# ADuCM4050 register map
Vendor: Analog Devices; Series: ADuCM4050; File version: 1p0
CPU: CM4 r0p1, little endian, MPU, FPU, 3 interrupt priority bits
Registers are 32-bit, read-write, reset 0x0 unless marked. A register's access mark holds for its fields unless they carry their own. Offsets are from the block's base; [hi:lo] are bit positions; <NAME> marks a mode.

## PMG0 — Power Management
Base 0x4004C000
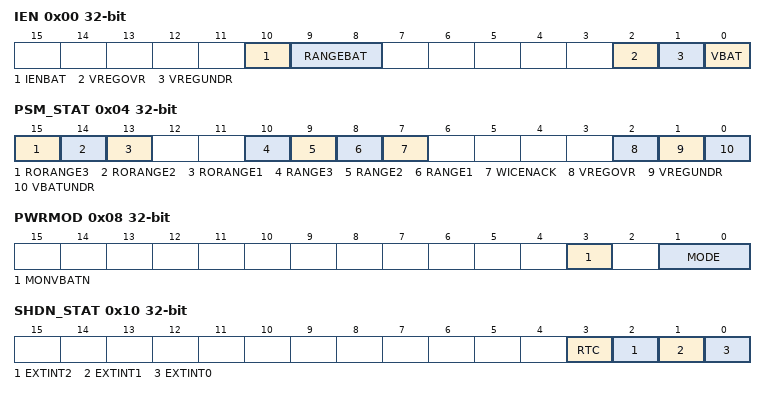
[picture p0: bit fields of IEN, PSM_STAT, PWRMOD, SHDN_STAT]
0x00 IEN — Power Supply Monitor Interrupt Enable
  [10] IENBAT range 0x00000000..0x00000001 — Interrupt Enable for VBAT Range
  [9:8] RANGEBAT — Battery Monitor Range
    0=region1 (Configure to generate interrupt if VBAT in Region1); 1=region2 (Configure to generate interrupt if VBAT in Region2); 2=region3 (Configure to generate interrupt if VBAT in Region3); 3=NA
  [2] VREGOVR range 0x00000000..0x00000001 — Enable Interrupt When VREG Over Voltage (Above 1.32V)
  [1] VREGUNDR range 0x00000000..0x00000001 — Enable Interrupt When VREG Under Voltage (Below 1V)
  [0] VBAT range 0x00000000..0x00000001 — Enable Interrupt for VBAT
0x04 PSM_STAT — Power Supply Monitor Status
  [15] RORANGE3 ro — VBAT Range3
  [14] RORANGE2 ro — VBAT Range2
  [13] RORANGE1 ro — VBAT Range1
    0=batstat1 (VBAT NOT in the range specified); 1=batstat0 (VBAT in the range specified)
  [10] RANGE3 — VBAT Range3
  [9] RANGE2 — VBAT Range2
  [8] RANGE1 — VBAT Range1
  [7] WICENACK ro — WIC Enable Acknowledge from Cortex
  [2] VREGOVR range 0x00000000..0x00000001 — Status Bit for Alarm Indicating Over Voltage for VREG
  [1] VREGUNDR range 0x00000000..0x00000001 — Status Bit for Alarm Indicating VREG is Below 1V
  [0] VBATUNDR range 0x00000000..0x00000001 — Status Bit Indicating an Alarm That Battery is Below 1.8V
0x08 PWRMOD — Power Mode Register
  [3] MONVBATN — Monitor VBAT During Hibernate Mode
    0=MONITOR_EN (VBAT monitor enabled in PMG block); 1=MONITOR_DIS (VBAT monitor disabled in PMG block)
  [1:0] MODE — Power Mode Bits
    0=FLEXI (Flexi Mode); 2=HIBERNATE (Hibernate Mode); 3=SHUTDOWN (Shutdown Mode)
0x0C PWRKEY — Key Protection for PMG_PWRMOD and PMG_SRAMRET
  [15:0] VALUE wo range 0x00000000..0x0000FFFF — Power Control Key
0x10 SHDN_STAT — Shutdown Status Register
  [3] RTC ro — Interrupt from RTC
  [2] EXTINT2 ro — Interrupt from External Interrupt 2
  [1] EXTINT1 ro — Interrupt from External Interrupt 1
  [0] EXTINT0 ro — Interrupt from External Interrupt 0
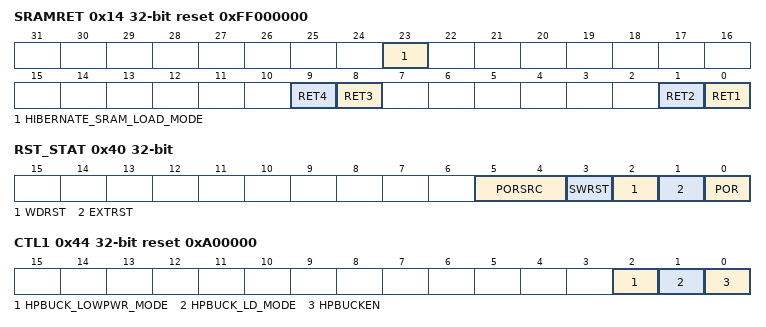
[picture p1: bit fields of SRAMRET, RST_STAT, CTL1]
0x14 SRAMRET reset 0xFF000000 — Control for Retention SRAM in Hibernate Mode
  [23] HIBERNATE_SRAM_LOAD_MODE range 0x00000000..0x00000001 — Hibernate Mode SRAM Load Mode Control
  [9] RET4 range 0x00000000..0x00000001 — Enable Retention Bank 6 and Bank 7 (32 KB)
  [8] RET3 range 0x00000000..0x00000001 — Enable Retention Bank 5 (32 KB)
  [1] RET2 range 0x00000000..0x00000001 — Enable Retention Bank 3 and Bank 4 (32 KB)
  [0] RET1 range 0x00000000..0x00000001 — Enable Retention Bank 1 (12 KB)
0x38 TRIM reset 0xA8AA2A2 — Trimming Bits
  [31:29] hibernate_load_mode — Hibernate Mode Load Mode Control
    0=HIGH_LOAD (High hibernate load); 7=LOW_LOAD (Low hibernate load)
0x40 RST_STAT — Reset Status
  [5:4] PORSRC ro — Power on Reset Source
    0=FAILSAFE_HV (POR triggered because VBAT drops below Fail Safe); 1=RST_VBAT (POR trigger because VBAT supply (VBAT < 1.7 V)); 2=RST_VREG (POR triggered because VDD supply (VDD < 1.08 V)); 3=FAILSAFE_LV (POR triggered because VREG drops below Fail Safe)
  [3] SWRST range 0x00000000..0x00000001 — Software Reset
  [2] WDRST range 0x00000000..0x00000001 — Watchdog Timeout
  [1] EXTRST range 0x00000000..0x00000001 — External Reset
  [0] POR range 0x00000000..0x00000001 — Power-on Reset
0x44 CTL1 reset 0xA00000 — HPBUCK Control
  [2] HPBUCK_LOWPWR_MODE — HP Buck Low Power Mode
    0=LOWPWRDisable (HPBUCK Low power mode is disabled); 1=LOWPWREnable (HPBUCK Low power mode is enabled)
  [1] HPBUCK_LD_MODE — HP Buck Load Mode
    0=HPBUCKLOWLOAD (HPBUCK Low load mode is enabled); 1=HPBUCKHIGHLOAD (HPBUCK High load mode is enabled)
  [0] HPBUCKEN range 0x00000000..0x00000001 — Enable HP Buck
